# RasbperryPi register map
File version: 1
Registers are 32-bit, read-write, reset 0x0 unless marked. A register's access mark holds for its fields unless they carry their own. Offsets are from the block's base; [hi:lo] are bit positions; {n}, {i} and the like mark numbered series; 'fields as' and 'values as' point back to an identical list.

## I2C0 — Derived from i2c0.h
Base 0x7E205000
Same registers: I2C1 0x7E804000, I2C2 0x7E805000
0x00 C 16-bit
  [15:0] data
0x04 S reset 0x50
  [31:0] data
0x08 DLEN 16-bit
  [15:0] data
0x0C A 7-bit
  [6:0] data
0x10 FIFO 8-bit
  [7:0] data
0x14 DIV 16-bit reset 0xDC
  [15:0] data
0x18 DEL reset 0x30
  [31:0] data
0x1C CLKT 16-bit reset 0x40
  [15:0] data

## I2C_SPI_SLV — Derived from i2c_spi_slv.h apb_id: 0x73506783
Base 0x7E214000
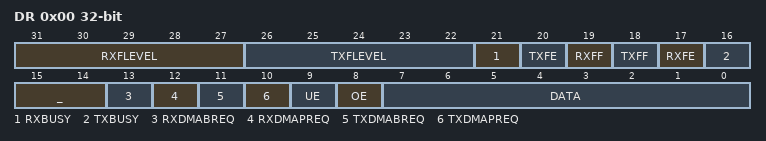
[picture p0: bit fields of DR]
0x00 DR
  [31:27] RXFLEVEL, [26:22] TXFLEVEL, [21] RXBUSY, [20] TXFE, [19] RXFF, [18] TXFF, [17] RXFE, [16] TXBUSY, [15:14] _, [13] RXDMABREQ, [12] RXDMAPREQ, [11] TXDMABREQ, [10] TXDMAPREQ, [9] UE, [8] OE, [7:0] DATA
0x04 RSR 6-bit
  [5] RXDMABREQ, [4] RXDMAPREQ, [3] TXDMABREQ, [2] TXDMAPREQ, [1] UE, [0] OE
0x08 SLV 7-bit
  [6:0] ADDR
0x0C CR 17-bit
  [16:14] _, [13] INV_TXF, [12] HOSTCTRLEN, [11] TESTFIFO, [10] INV_RXF, [9] RXE, [8] TXE, [7] BRK, [6] ENCTRL, [5] ENSTAT, [4] CPOL, [3] CPHA, [2] I2C, [1] SPI, [0] EN
0x10 FR 16-bit reset 0x12
  [15:11] RXFLEVEL, [10] TXFLEVEL, [10:6] _, [5] RXBUSY, [4] TXFE, [3] RXFF, [2] TXFF, [1] RXFE, [0] TXBUSY
0x14 IFLS 12-bit reset 0x92
  [11:9] RXIFPSEL, [8:6] TXIFPSEL, [5:3] RXIFLSEL, [2:0] TXIFLSEL
0x18 IMSC 4-bit
  [3] OEIM, [2] BEIM, [1] TXIM, [0] RXIM
0x1C RIS 4-bit reset 0x2
  [3] OERIS, [2] BERIS, [1] TXRIS, [0] RXRIS
0x20 MIS 4-bit
  [3] OEMIS, [2] BEMIS, [1] TXMIS, [0] RXMIS
0x24 ICR 4-bit
  [3] OEIC, [2] BEIC, [1] TXIC, [0] RXIC
0x28 DMACR 3-bit
  [2] DMAONERR, [1] TXDMAE, [0] RXDMAE
0x2C TDR 8-bit
  [7:0] DATA
0x30 VCSTAT 4-bit
  [3:0] DATA
0x34 HCTRL 8-bit
  [7:0] DATA
0x38 DEBUG1 26-bit reset 0xE
  [25:0] DATA
0x3C DEBUG2 24-bit
  [23:0] DATA

## IC0 — Derived from intctrl0.h apb_id: 0x494E5445
Base 0x7E002000
Same registers: IC1 0x7E002800
0x00 C 4-bit
  [3:0] data
0x04 S 27-bit ro reset not defined
  [26:0] data
0x08 SRC0 ro reset not defined
  [31:0] data
0x0C SRC1 ro reset not defined
  [31:0] data
{0x10+4i} MASK{i} 31-bit (i=0..7)
  [30:0] data
0x30 VADDR
  [31:0] data
0x34 WAKEUP
  [31:0] data
0x38 PROFILE 16-bit reset not defined
  [15:0] data
0x40 FORCE0
  [31:0] data
0x44 FORCE1
  [31:0] data
0x48 FORCE0_SET
  [31:0] data
0x4C FORCE1_SET
  [31:0] data
0x50 FORCE0_CLR
  [31:0] data
0x54 FORCE1_CLR
  [31:0] data

## JP — Derived from jpeg_top.h apb_id: 0x4A504547
Base 0x7E005000
0x00 CTRL reset not defined
  [31:0] data

## L2 — Derived from l2_cache_ctrl.h apb_id: 0x4C324343
Base 0x7EE01000
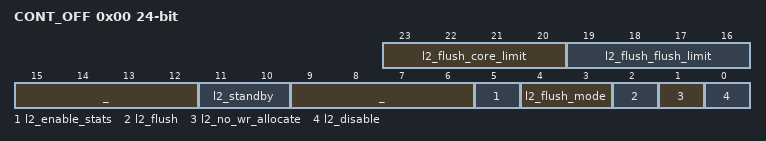
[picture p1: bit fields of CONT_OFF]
0x00 CONT_OFF 24-bit
  [23:20] l2_flush_core_limit, [19:16] l2_flush_flush_limit, [15:12] _, [11:10] l2_standby, [9:6] _, [5] l2_enable_stats, [4:3] l2_flush_mode, [2] l2_flush, [1] l2_no_wr_allocate, [0] l2_disable
0x00 RD_HITS reset not defined
  [31:0] data
0x04 FLUSH_STA 28-bit
  [27:0] data
0x04 RD_MISSES ro reset not defined
  [31:0] data
0x08 FLUSH_END 28-bit reset 0xE0
  [27:0] data
0x08 WR_HITS ro reset not defined
  [31:0] data
0x0C WR_MISSES ro reset not defined
  [31:0] data
0x10 WR_BACKS ro reset not defined
  [31:0] data
0x14 IN_FLIGHT 4-bit ro reset not defined
  [3:0] data
0x1C STALLS ro reset not defined
  [31:0] data
0x20 TAG_STALLS ro reset not defined
  [31:0] data
0x24 SD_STALLS ro reset not defined
  [31:0] data
0x80 L2_ALIAS_EXCEPTION
  [31:0] data
0x84 L2_ALIAS_EXCEPTION_ID ro
  [31:0] data
0x88 L2_ALIAS_EXCEPTION_ADDR ro
  [31:0] data

## MPHI — Derived from mphi.h apb_id: 0x6D706869
Base 0x7E006000
0x00 C0INDDA reset not defined
  [31:0] START
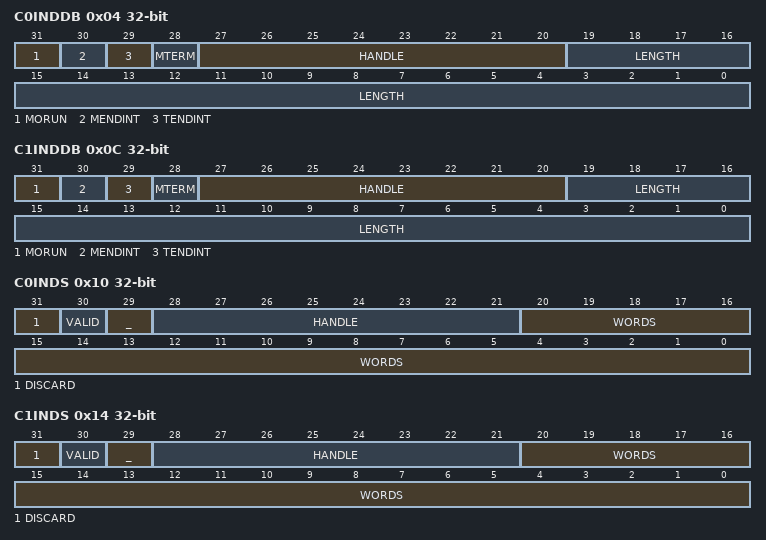
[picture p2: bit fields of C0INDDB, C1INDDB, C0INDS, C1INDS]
0x04 C0INDDB reset not defined
  [31] MORUN, [30] MENDINT, [29] TENDINT, [28] MTERM, [27:20] HANDLE, [19:0] LENGTH
0x08 C1INDDA reset not defined
  [31:0] START
0x0C C1INDDB reset not defined
  fields as C0INDDB
0x10 C0INDS reset not defined
  [31] DISCARD, [30] VALID, [29] _, [28:21] HANDLE, [20:0] WORDS
0x14 C1INDS reset not defined
  [31] DISCARD, [30] VALID, [29] _, [28:21] HANDLE, [20:0] WORDS
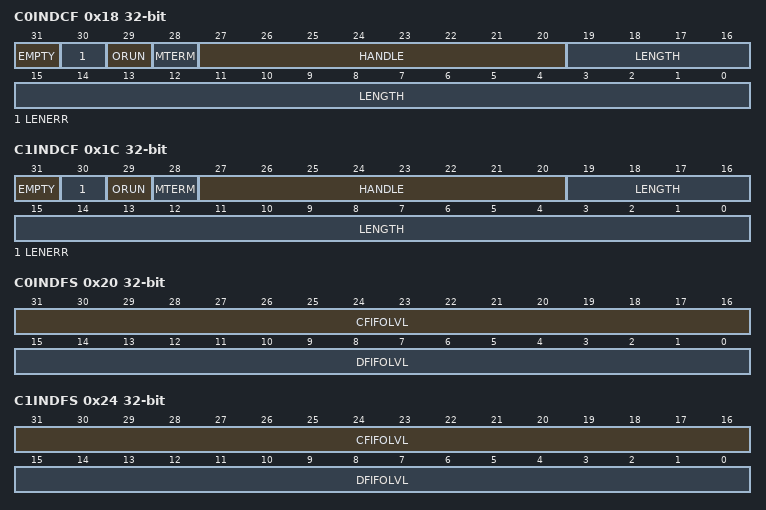
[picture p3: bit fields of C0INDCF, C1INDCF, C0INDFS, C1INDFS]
0x18 C0INDCF reset not defined
  [31] EMPTY, [30] LENERR, [29] ORUN, [28] MTERM, [27:20] HANDLE, [19:0] LENGTH
0x1C C1INDCF reset not defined
  fields as C0INDCF
0x20 C0INDFS reset not defined
  [31:16] CFIFOLVL, [15:0] DFIFOLVL
0x24 C1INDFS reset not defined
  [31:16] CFIFOLVL, [15:0] DFIFOLVL
0x28 OUTDDA reset not defined
  [31:0] START
0x2C OUTDDB 30-bit reset not defined
  [29] TENDINT, [28] CHANNEL, [27:20] HANDLE, [19:0] LENGTH
0x30 OUTDS 31-bit reset not defined
  [30] VALID, [29] _, [28:21] HANDLE, [20:0] WORDS
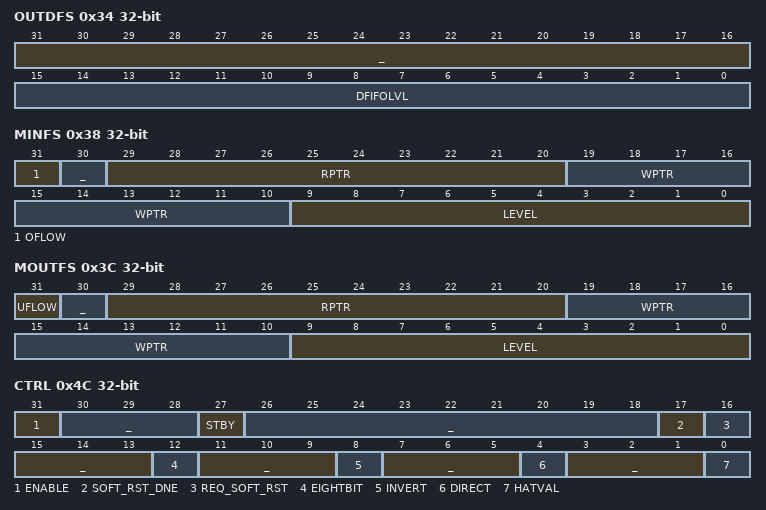
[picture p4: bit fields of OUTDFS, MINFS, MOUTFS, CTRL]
0x34 OUTDFS reset not defined
  [31:16] _, [15:0] DFIFOLVL
0x38 MINFS reset not defined
  [31] OFLOW, [30] _, [29:20] RPTR, [19:10] WPTR, [9:0] LEVEL
0x3C MOUTFS reset not defined
  [31] UFLOW, [30] _, [29:20] RPTR, [19:10] WPTR, [9:0] LEVEL
0x40 AXIPRIV 9-bit reset not defined
  [8] HSPECEN, [7] _, [6:4] RXPROT, [3] _, [2:0] TXPROT
0x44 RXAXICFG 17-bit reset not defined
  [16:8] INTHRESH, [7:4] RXPPRIO, [3:0] RXNPRIO
0x48 TXAXICFG 17-bit reset not defined
  [16:8] INTHRESH, [7:4] TXPPRIO, [3:0] TXNPRIO
0x4C CTRL reset not defined
  [31] ENABLE, [30:28] _, [27] STBY, [26:18] _, [17] SOFT_RST_DNE, [16] REQ_SOFT_RST, [15:13] _, [12] EIGHTBIT, [11:9] _, [8] INVERT, [7:5] _, [4] DIRECT, [3:1] _, [0] HATVAL
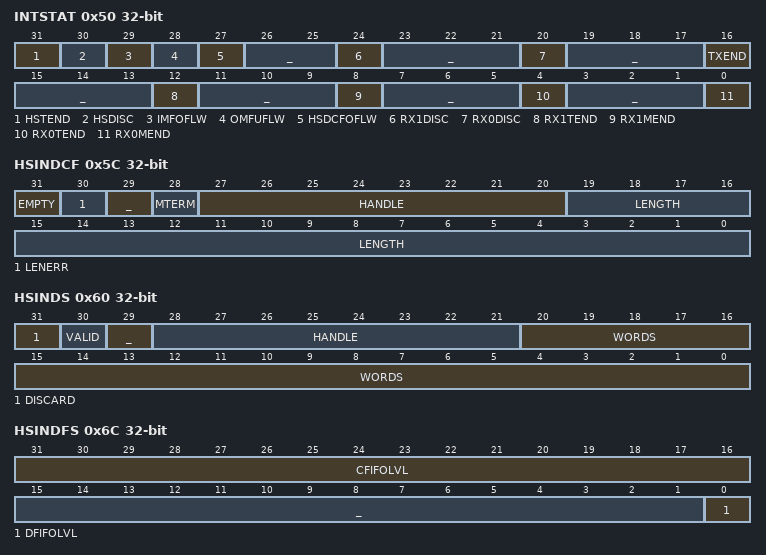
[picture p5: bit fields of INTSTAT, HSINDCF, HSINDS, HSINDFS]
0x50 INTSTAT reset not defined
  [31] HSTEND, [30] HSDISC, [29] IMFOFLW, [28] OMFUFLW, [27] HSDCFOFLW, [26:25] _, [24] RX1DISC, [23:21] _, [20] RX0DISC, [19:17] _, [16] TXEND, [15:13] _, [12] RX1TEND, [11:9] _, [8] RX1MEND, [7:5] _, [4] RX0TEND, [3:1] _, [0] RX0MEND
0x54 VERSION ro reset not defined
  [31:0] data
0x58 INTCTRL 21-bit reset not defined
  [20] HSDCOFLW, [19:17] _, [16] HSDISC, [15:13] _, [12] OMFUFLW, [11:9] _, [8] IMFOFLW, [7:5] _, [4] RX1DISC, [3:1] _, [0] RX0DISC
0x5C HSINDCF reset not defined
  [31] EMPTY, [30] LENERR, [29] _, [28] MTERM, [27:20] HANDLE, [19:0] LENGTH
0x60 HSINDS reset not defined
  [31] DISCARD, [30] VALID, [29] _, [28:21] HANDLE, [20:0] WORDS
0x64 HSINDDA reset not defined
  [31:0] START
0x68 HSINDDB 30-bit reset not defined
  [29] TENDINT, [28] _, [27:20] HANDLE, [19:0] LENGTH
0x6C HSINDFS reset not defined
  [31:16] CFIFOLVL, [15:1] _, [0] DFIFOLVL
